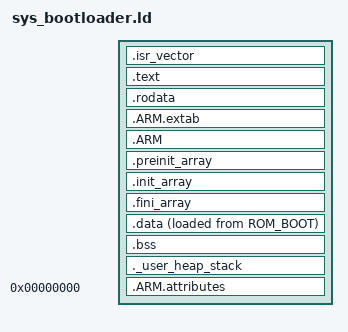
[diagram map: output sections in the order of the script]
/*
******************************************************************************
**
**  File        : sys_bootloader.ld
**  Author      : Sebastián Del Moral Gallardo (Based on STM32 autogenerated file)
**  Abstract    : Linker script for STM32G070RBTx series
**                128Kbytes FLASH and 36Kbytes RAM
**
**                Allocate elements for Bootloader application.
**
*****************************************************************************
*/

/* Add system memory map */
INCLUDE Linker/sys_memory_map.ld

/* Entry Point */
ENTRY(Reset_Handler)

/* Highest address of the user mode stack */
_estack = 0x20009000;       /* end of RAM */

/* Generate a link error if heap and stack don't fit into RAM */
_Min_Heap_Size = 0x200;     /* required amount of heap  */
_Min_Stack_Size = 0x400;    /* required amount of stack */

/* Define output sections */
SECTIONS
{
  /* The startup code goes first into ROM_BOOT */
  .isr_vector :
  {
    . = ALIGN(4);
    KEEP(*(.isr_vector)) /* Startup code */
    . = ALIGN(4);
  } >ROM_BOOT

  /* The program code and other data goes into ROM_BOOT */
  .text :
  {
    . = ALIGN(4);
    *(.text)           /* .text sections (code) */
    *(.text*)          /* .text* sections (code) */
    *(.glue_7)         /* glue arm to thumb code */
    *(.glue_7t)        /* glue thumb to arm code */
    *(.eh_frame)

    KEEP (*(.init))
    KEEP (*(.fini))

    . = ALIGN(4);
    _etext = .;        /* define a global symbols at end of code */
  } >ROM_BOOT

  /* Constant data goes into ROM_BOOT */
  .rodata :
  {
    . = ALIGN(4);
    *(.rodata)         /* .rodata sections (constants, strings, etc.) */
    *(.rodata*)        /* .rodata* sections (constants, strings, etc.) */
    . = ALIGN(4);
  } >ROM_BOOT

  .ARM.extab   : { *(.ARM.extab* .gnu.linkonce.armextab.*) } >ROM_BOOT
  .ARM : {
    __exidx_start = .;
    *(.ARM.exidx*)
    __exidx_end = .;
  } >ROM_BOOT

  .preinit_array     :
  {
    PROVIDE_HIDDEN (__preinit_array_start = .);
    KEEP (*(.preinit_array*))
    PROVIDE_HIDDEN (__preinit_array_end = .);
  } >ROM_BOOT
  .init_array :
  {
    PROVIDE_HIDDEN (__init_array_start = .);
    KEEP (*(SORT(.init_array.*)))
    KEEP (*(.init_array*))
    PROVIDE_HIDDEN (__init_array_end = .);
  } >ROM_BOOT
  .fini_array :
  {
    PROVIDE_HIDDEN (__fini_array_start = .);
    KEEP (*(SORT(.fini_array.*)))
    KEEP (*(.fini_array*))
    PROVIDE_HIDDEN (__fini_array_end = .);
  } >ROM_BOOT

  /* used by the startup to initialize data */
  _sidata = LOADADDR(.data);

  /* Initialized data sections goes into RAM, load LMA copy after code */
  .data : 
  {
    . = ALIGN(4);
    _sdata = .;        /* create a global symbol at data start */
    *(.data)           /* .data sections */
    *(.data*)          /* .data* sections */

    . = ALIGN(4);
    _edata = .;        /* define a global symbol at data end */
  } >RAM AT> ROM_BOOT

  
  /* Uninitialized data section */
  . = ALIGN(4);
  .bss :
  {
    /* This is used by the startup in order to initialize the .bss secion */
    _sbss = .;         /* define a global symbol at bss start */
    __bss_start__ = _sbss;
    *(.bss)
    *(.bss*)
    *(COMMON)

    . = ALIGN(4);
    _ebss = .;         /* define a global symbol at bss end */
    __bss_end__ = _ebss;
  } >RAM

  /* User_heap_stack section, used to check that there is enough RAM left */
  ._user_heap_stack :
  {
    . = ALIGN(8);
    PROVIDE ( end = . );
    PROVIDE ( _end = . );
    . = . + _Min_Heap_Size;
    . = . + _Min_Stack_Size;
    . = ALIGN(8);
  } >RAM

  /* Remove information from the standard libraries */
  /DISCARD/ :
  {
    libc.a ( * )
    libm.a ( * )
    libgcc.a ( * )
  }

  .ARM.attributes 0 : { *(.ARM.attributes) }
}


